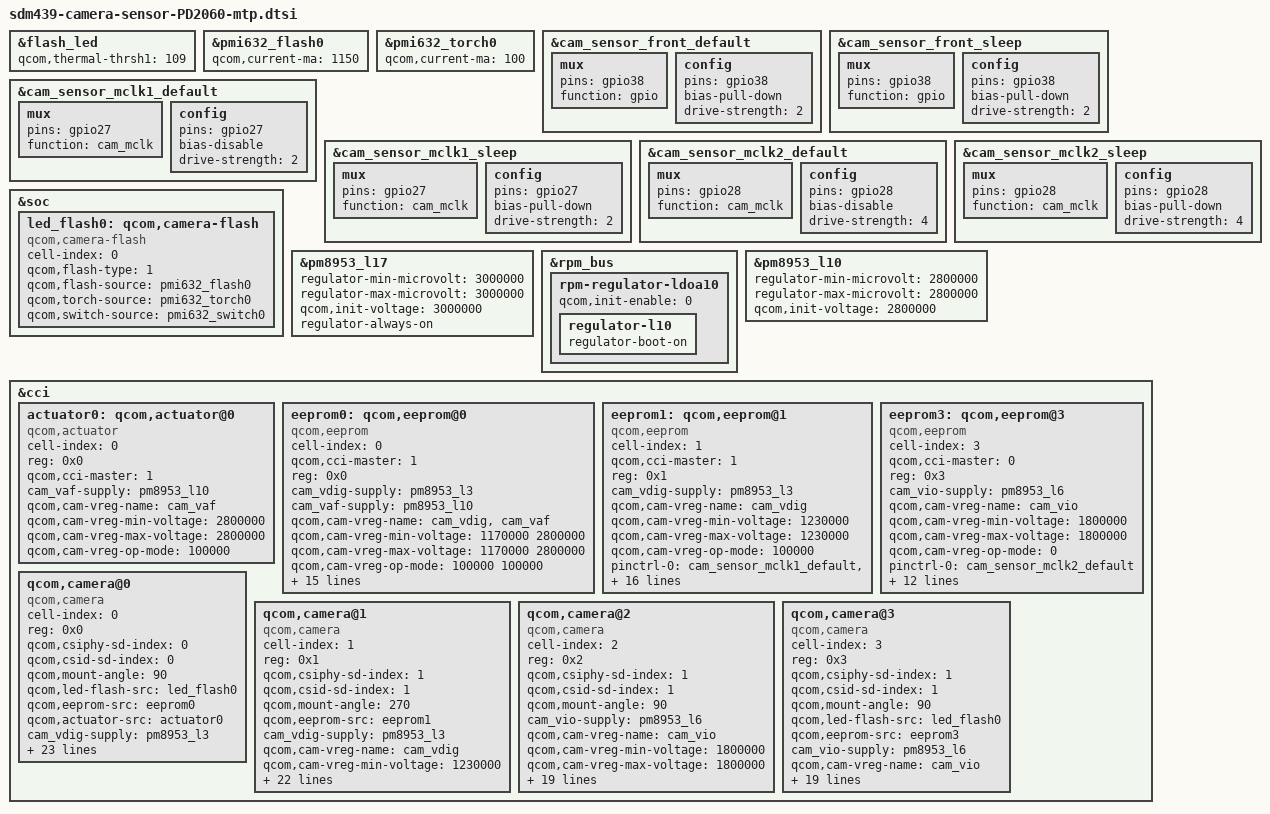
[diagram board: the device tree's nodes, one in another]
/*
 * Copyright (c) 2015-2016, 2018-2019 The Linux Foundation. All rights reserved.
 *
 * This program is free software; you can redistribute it and/or modify
 * it under the terms of the GNU General Public License version 2 and
 * only version 2 as published by the Free Software Foundation.
 *
 * This program is distributed in the hope that it will be useful,
 * but WITHOUT ANY WARRANTY; without even the implied warranty of
 * MERCHANTABILITY or FITNESS FOR A PARTICULAR PURPOSE.  See the
 * GNU General Public License for more details.
 */

#include <dt-bindings/clock/msm-clocks-8952.h>

&flash_led {
	qcom,thermal-thrsh1 =  <109>;
};

&pmi632_flash0 {
	qcom,current-ma = <1150>;
};

&pmi632_torch0 {
	qcom,current-ma = <100>;
};

&cam_sensor_front_default {
	/* RESET, STANDBY */
	mux {
		pins = "gpio38";
		function = "gpio";
	};

	config {
		pins = "gpio38";
		bias-pull-down; /*PULL DOWN*/
		drive-strength = <2>; /* 2 MA */
	};
};

&cam_sensor_front_sleep {
	/* RESET, STANDBY */
	mux {
		pins = "gpio38";
		function = "gpio";
	};

	config {
		pins = "gpio38";
		bias-pull-down; /*PULL DOWN*/
		drive-strength = <2>; /* 2 MA */
	};
};

&cam_sensor_mclk1_default {
	/* MCLK1 */
	mux {
		/* CLK, DATA */
		pins = "gpio27";
		function = "cam_mclk";
	};

	config {
		pins = "gpio27";
		bias-disable; /* No PULL */
		drive-strength = <2>; /* 2 MA */
	};
};

&cam_sensor_mclk1_sleep {
	/* MCLK1 */
	mux {
		/* CLK, DATA */
		pins = "gpio27";
		function = "cam_mclk";
	};

	config {
		pins = "gpio27";
		bias-pull-down; /* PULL DOWN */
		drive-strength = <2>; /* 2 MA */
	};
};

&cam_sensor_mclk2_default {
	/* MCLK2 */
	mux {
		/* CLK, DATA */
		pins = "gpio28";
		function = "cam_mclk";
	};

	config {
		pins = "gpio28";
		bias-disable; /* No PULL */
		drive-strength = <4>; /* 2 MA */
	};
};

&cam_sensor_mclk2_sleep {
	/* MCLK2 */
	mux {
		/* CLK, DATA */
		pins = "gpio28";
		function = "cam_mclk";
	};

	config {
		pins = "gpio28";
		bias-pull-down; /* PULL DOWN */
		drive-strength = <4>; /* 2 MA */
	};
};

&soc {
	led_flash0: qcom,camera-flash {
		cell-index = <0>;
		compatible = "qcom,camera-flash";
		qcom,flash-type = <1>;
		qcom,flash-source = <&pmi632_flash0>;
		qcom,torch-source = <&pmi632_torch0>;
		qcom,switch-source = <&pmi632_switch0>;
		status = "ok";
	};
};
/*vsen sensor add prox vled*/
&pm8953_l17 {
	regulator-min-microvolt = <3000000>;
	regulator-max-microvolt = <3000000>;
	qcom,init-voltage = <3000000>;
	regulator-always-on;
};
/*vsen sensor add prox vled*/

&rpm_bus {
	rpm-regulator-ldoa10 {
		qcom,init-enable = <0>;
		regulator-l10 {
			regulator-boot-on;
		};
	};
};

&pm8953_l10 {
	regulator-min-microvolt = <2800000>;
	regulator-max-microvolt = <2800000>;
	qcom,init-voltage = <2800000>;
	status = "okay";
};

&cci {
	actuator0: qcom,actuator@0 {
		cell-index = <0>;
		reg = <0x0>;
		compatible = "qcom,actuator";
		qcom,cci-master = <1>;
		cam_vaf-supply = <&pm8953_l10>;
		qcom,cam-vreg-name = "cam_vaf";
		qcom,cam-vreg-min-voltage = <2800000>;
		qcom,cam-vreg-max-voltage = <2800000>;
		qcom,cam-vreg-op-mode = <100000>;
	};

	eeprom0: qcom,eeprom@0 {
		cell-index = <0>;
		compatible = "qcom,eeprom";
		qcom,cci-master = <1>;
		reg = <0x0>;
		cam_vdig-supply = <&pm8953_l3>;
		cam_vaf-supply = <&pm8953_l10>;
		qcom,cam-vreg-name = "cam_vdig", "cam_vaf";
		qcom,cam-vreg-min-voltage = <1170000 2800000>;
		qcom,cam-vreg-max-voltage = <1170000 2800000>;
		qcom,cam-vreg-op-mode = <100000 100000>;
		pinctrl-names = "cam_default", "cam_suspend";
		pinctrl-0 = <&cam_sensor_mclk0_default
			&cam_sensor_rear_reset>;
		pinctrl-1 = <&cam_sensor_mclk0_sleep
			&cam_sensor_rear_reset_sleep>;
		gpios = <&tlmm 26 0>,
			<&tlmm 50 0>,
			<&tlmm 35 0>,
			<&tlmm 36 0>;
		qcom,gpio-vio = <1>;
		qcom,gpio-vana = <2>;
		qcom,gpio-reset = <3>;
		qcom,gpio-req-tbl-num = <0 1 2 3>;
		qcom,gpio-req-tbl-flags = <1 0 0 0>;
		qcom,gpio-req-tbl-label = "CAMIF_MCLK0", "CAM_VIO0", "CAM_VANA0", "CAM_RESET0";
		status = "ok";
		clocks = <&clock_gcc clk_mclk0_clk_src>,
			<&clock_gcc clk_gcc_camss_mclk0_clk>;
		clock-names = "cam_src_clk", "cam_clk";
		qcom,clock-rates = <24000000 0>;
	};

	eeprom1: qcom,eeprom@1 {
		cell-index = <1>;
		compatible = "qcom,eeprom";
		qcom,cci-master = <1>;
		reg = <0x1>;
		cam_vdig-supply = <&pm8953_l3>;
		qcom,cam-vreg-name = "cam_vdig";
		qcom,cam-vreg-min-voltage = <1230000>;
		qcom,cam-vreg-max-voltage = <1230000>;
		qcom,cam-vreg-op-mode = <100000>;
		pinctrl-names = "cam_default", "cam_suspend";
		pinctrl-0 = <&cam_sensor_mclk1_default
			&cam_sensor_front_default>;
		pinctrl-1 = <&cam_sensor_mclk1_sleep
			&cam_sensor_front_sleep>;
		gpios = <&tlmm 27 0>,
			<&tlmm 50 0>,
			<&tlmm 35 0>,
			<&tlmm 68 0>,
			<&tlmm 38 0>;
		qcom,gpio-vio = <1>;
		qcom,gpio-vana = <2>;
		qcom,gpio-vdig = <3>;
		qcom,gpio-reset = <4>;
		qcom,gpio-req-tbl-num = <0 1 2 3 4>;
		qcom,gpio-req-tbl-flags = <1 0 0 0 0>;
		qcom,gpio-req-tbl-label = "CAMIF_MCLK1", "CAM_VIO1", "CAM_VANA1", "CAM_VDIG1", "CAM_RESET1";
		status = "ok";
		clocks = <&clock_gcc clk_mclk1_clk_src>,
			<&clock_gcc clk_gcc_camss_mclk1_clk>;
		clock-names = "cam_src_clk", "cam_clk";
		qcom,clock-rates = <24000000 0>;
	};

	eeprom3: qcom,eeprom@3 {
		cell-index = <3>;
		compatible = "qcom,eeprom";
		qcom,cci-master = <0>;
		reg = <0x3>;
		cam_vio-supply = <&pm8953_l6>;
		qcom,cam-vreg-name = "cam_vio";
		qcom,cam-vreg-min-voltage = <1800000>;
		qcom,cam-vreg-max-voltage = <1800000>;
		qcom,cam-vreg-op-mode = <0>;
		pinctrl-names = "cam_default", "cam_suspend";
		pinctrl-0 = <&cam_sensor_mclk2_default>;
		pinctrl-1 = <&cam_sensor_mclk2_sleep>;
		gpios = <&tlmm 28 0>,
			<&tlmm 50 0>,
			<&tlmm 25 0>,
			<&tlmm 13 0>;
		qcom,gpio-vio = <1>;
		qcom,gpio-vana = <2>;
		qcom,gpio-reset = <3>;
		qcom,gpio-req-tbl-num = <0 1 2 3>;
		qcom,gpio-req-tbl-flags = <1 0 0 0>;
		qcom,gpio-req-tbl-label = "CAMIF_MCLK3", "CAM_VIO3", "CAM_VANA3", "CAM_RESET3";
		status = "ok";
		clocks = <&clock_gcc clk_mclk2_clk_src>,
			<&clock_gcc clk_gcc_camss_mclk2_clk>;
		clock-names = "cam_src_clk", "cam_clk";
		qcom,clock-rates = <19200000 0>;
	};

	qcom,camera@0 {
		cell-index = <0>;
		compatible = "qcom,camera";
		reg = <0x0>;
		qcom,csiphy-sd-index = <0>;
		qcom,csid-sd-index = <0>;
		qcom,mount-angle = <90>;
		qcom,led-flash-src = <&led_flash0>;
		qcom,eeprom-src = <&eeprom0>;
		qcom,actuator-src = <&actuator0>;
		cam_vdig-supply = <&pm8953_l3>;
		cam_vaf-supply = <&pm8953_l10>;
		qcom,cam-vreg-name = "cam_vdig", "cam_vaf";
		qcom,cam-vreg-min-voltage = <1170000 2800000>;
		qcom,cam-vreg-max-voltage = <1170000 2800000>;
		qcom,cam-vreg-op-mode = <100000 100000>;
		pinctrl-names = "cam_default", "cam_suspend";
		pinctrl-0 = <&cam_sensor_mclk0_default
				&cam_sensor_rear_reset>;
		pinctrl-1 = <&cam_sensor_mclk0_sleep
				&cam_sensor_rear_reset_sleep>;
		gpios = <&tlmm 26 0>,
			<&tlmm 50 0>,
			<&tlmm 35 0>,
			<&tlmm 36 0>;
		qcom,gpio-vio = <1>;
		qcom,gpio-vana = <2>;
		qcom,gpio-reset = <3>;
		qcom,gpio-req-tbl-num = <0 1 2 3>;
		qcom,gpio-req-tbl-flags = <1 0 0 0>;
		qcom,gpio-req-tbl-label = "CAMIF_MCLK0", "CAM_VIO0", "CAM_VANA0", "CAM_RESET0";
		qcom,sensor-position = <0>;
		qcom,sensor-mode = <0>;
		qcom,cci-master = <1>;
		status = "ok";
		clocks = <&clock_gcc clk_mclk0_clk_src>,
				<&clock_gcc clk_gcc_camss_mclk0_clk>;
		clock-names = "cam_src_clk", "cam_clk";
		qcom,clock-rates = <24000000 0>;
	};

	qcom,camera@1 {
		cell-index = <1>;
		compatible = "qcom,camera";
		reg = <0x1>;
		qcom,csiphy-sd-index = <1>;
		qcom,csid-sd-index = <1>;
		qcom,mount-angle = <270>;
		qcom,eeprom-src = <&eeprom1>;
		cam_vdig-supply = <&pm8953_l3>;
		qcom,cam-vreg-name = "cam_vdig";
		qcom,cam-vreg-min-voltage = <1230000>;
		qcom,cam-vreg-max-voltage = <1230000>;
		qcom,cam-vreg-op-mode = <100000>;
		pinctrl-names = "cam_default", "cam_suspend";
		pinctrl-0 = <&cam_sensor_mclk1_default
				&cam_sensor_front_default>;
		pinctrl-1 = <&cam_sensor_mclk1_sleep
				&cam_sensor_front_sleep>;
		gpios = <&tlmm 27 0>,
			<&tlmm 50 0>,
			<&tlmm 35 0>,
			<&tlmm 68 0>,
			<&tlmm 38 0>;
		qcom,gpio-vio = <1>;
		qcom,gpio-vana = <2>;
		qcom,gpio-vdig = <3>;
		qcom,gpio-reset = <4>;
		qcom,gpio-req-tbl-num = <0 1 2 3 4>;
		qcom,gpio-req-tbl-flags = <1 0 0 0 0>;
		qcom,gpio-req-tbl-label = "CAMIF_MCLK1", "CAM_VIO1", "CAM_VANA1", "CAM_VDIG1", "CAM_RESET1";
		qcom,sensor-position = <1>;
		qcom,sensor-mode = <1>;
		qcom,cci-master = <1>;
		clocks = <&clock_gcc clk_mclk1_clk_src>,
				<&clock_gcc clk_gcc_camss_mclk1_clk>;
		clock-names = "cam_src_clk", "cam_clk";
		qcom,clock-rates = <24000000 0>;
	};

	qcom,camera@2 {
		cell-index = <2>;
		compatible = "qcom,camera";
		reg = <0x2>;
		qcom,csiphy-sd-index = <1>;
		qcom,csid-sd-index = <1>;
		qcom,mount-angle = <90>;
		cam_vio-supply = <&pm8953_l6>;
		qcom,cam-vreg-name = "cam_vio";
		qcom,cam-vreg-min-voltage = <1800000>;
		qcom,cam-vreg-max-voltage = <1800000>;
		qcom,cam-vreg-op-mode = <0>;
		pinctrl-names = "cam_default", "cam_suspend";
		pinctrl-0 = <&cam_sensor_mclk2_default>;
		pinctrl-1 = <&cam_sensor_mclk2_sleep>;
		gpios = <&tlmm 28 0>,
			<&tlmm 50 0>,
			<&tlmm 35 0>,
			<&tlmm 25 0>,
			<&tlmm 90 0>;
		qcom,gpio-vio = <1>;
		qcom,gpio-vana = <2>;
		qcom,gpio-custom1 = <3>;
		qcom,gpio-reset = <4>;
		qcom,gpio-req-tbl-num = <0 1 2 3 4>;
		qcom,gpio-req-tbl-flags = <1 0 0 0 0>;
		qcom,gpio-req-tbl-label = "CAMIF_MCLK2", "CAM_VIO2", "CAM_VANA2", "CAM_CUSTOM1", "CAM_RESET2";
		qcom,sensor-position = <0>;
		qcom,sensor-mode = <0>;
		qcom,cci-master = <0>;
		status = "ok";
		clocks = <&clock_gcc clk_mclk2_clk_src>,
			<&clock_gcc clk_gcc_camss_mclk2_clk>;
		clock-names = "cam_src_clk", "cam_clk";
		qcom,clock-rates = <24000000 0>;
	};

	qcom,camera@3 {
		cell-index = <3>;
		compatible = "qcom,camera";
		reg = <0x3>;
		qcom,csiphy-sd-index = <1>;
		qcom,csid-sd-index = <1>;
		qcom,mount-angle = <90>;
		qcom,led-flash-src = <&led_flash0>;
		qcom,eeprom-src = <&eeprom3>;
		cam_vio-supply = <&pm8953_l6>;
		qcom,cam-vreg-name = "cam_vio";
		qcom,cam-vreg-min-voltage = <1800000>;
		qcom,cam-vreg-max-voltage = <1800000>;
		qcom,cam-vreg-op-mode = <0>;
		pinctrl-names = "cam_default", "cam_suspend";
		pinctrl-0 = <&cam_sensor_mclk2_default>;
		pinctrl-1 = <&cam_sensor_mclk2_sleep>;
		gpios = <&tlmm 28 0>,
			<&tlmm 50 0>,
			<&tlmm 35 0>,
			<&tlmm 13 0>;
		qcom,gpio-vio = <1>;
		qcom,gpio-vana = <2>;
		qcom,gpio-reset = <3>;
		qcom,gpio-req-tbl-num = <0 1 2 3>;
		qcom,gpio-req-tbl-flags = <1 0 0 0>;
		qcom,gpio-req-tbl-label = "CAMIF_MCLK3", "CAM_VIO3", "CAM_VANA3", "CAM_RESET3";
		qcom,sensor-position = <0>;
		qcom,sensor-mode = <0>;
		qcom,cci-master = <0>;
		status = "ok";
		clocks = <&clock_gcc clk_mclk2_clk_src>,
			<&clock_gcc clk_gcc_camss_mclk2_clk>;
		clock-names = "cam_src_clk", "cam_clk";
		qcom,clock-rates = <19200000 0>;
	};
};
